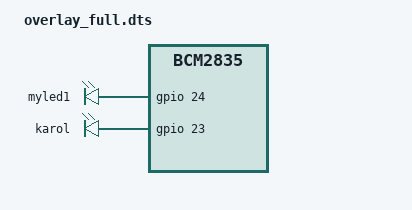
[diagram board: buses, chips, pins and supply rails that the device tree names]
/dts-v1/;
/plugin/;

/ {
	compatible = "brcm,bcm2835";

	fragment@0 {
		// Configure the gpio pin controller
		target = <&gpio>;
		__overlay__ {
			led_pin: led_pins@24 {
				brcm,pins = <24>; // gpio number
				brcm,function = <1>; // 0 = input, 1 = output
				brcm,pull = <0>; // 0 = none, 1 = pull down, 2 = pull up
			};
            led_pin1: led_pins@23 {
				brcm,pins = <23>; // gpio number
				brcm,function = <1>; // 0 = input, 1 = output
				brcm,pull = <0>; // 0 = none, 1 = pull down, 2 = pull up
			};
		};
	};
	fragment@1 {
		target-path = "/";
		__overlay__ {
			leds: leds@0 {
				compatible = "gpio-leds";
				pinctrl-names = "default";
				pinctrl-0 = <&led_pin>;
				status = "okay";

				led: led {
			                label = "myled1";
					        gpios = <&gpio 24 0>;
			                linux,default-trigger = "cpu1";
				};
			};
            leds1: leds@1 {
				compatible = "gpio-leds";
				pinctrl-names = "default";
				pinctrl-0 = <&led_pin1>;
				status = "okay";

				led1: led {
			                label = "karol";
					        gpios = <&gpio 23 0>;
			                linux,default-trigger = "heartbeat";
				};
			};
		};
	};
};
